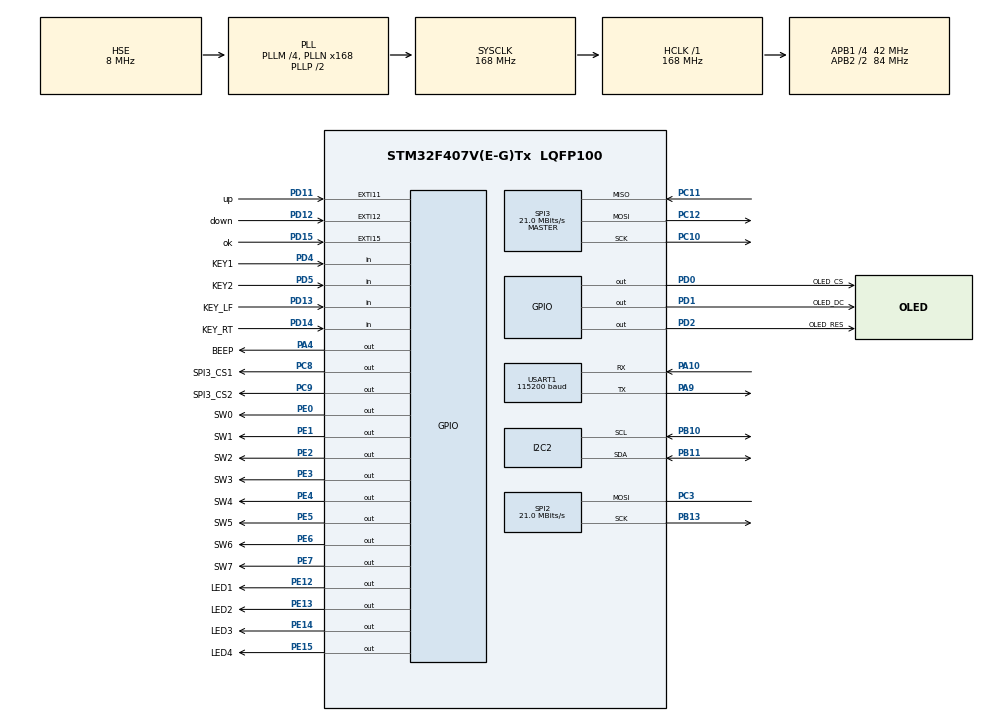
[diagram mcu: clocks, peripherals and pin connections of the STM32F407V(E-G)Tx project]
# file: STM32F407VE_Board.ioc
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Mcu.Family=STM32F4
Mcu.Name=STM32F407V(E-G)Tx
Mcu.Package=LQFP100
NVIC.EXTI15_10_IRQn=true\:6\:0\:true\:false\:true\:true\:true
NVIC.PriorityGroup=NVIC_PRIORITYGROUP_4
NVIC.USART1_IRQn=true\:2\:0\:true\:false\:true\:true\:true
PA10.Mode=Asynchronous
PA10.Signal=USART1_RX
PA13.Mode=Serial_Wire
PA13.Signal=SYS_JTMS-SWDIO
PA14.Mode=Serial_Wire
PA14.Signal=SYS_JTCK-SWCLK
PA4.GPIO_Label=BEEP
PA4.GPIO_PuPd=GPIO_PULLUP
PA4.Signal=GPIO_Output
PA9.Mode=Asynchronous
PA9.Signal=USART1_TX
PB10.Mode=I2C
PB10.Signal=I2C2_SCL
PB11.Mode=I2C
PB11.Signal=I2C2_SDA
PB13.Mode=Simplex_Bidirectional_Master
PB13.Signal=SPI2_SCK
PC10.Mode=Full_Duplex_Master
PC10.Signal=SPI3_SCK
PC11.Mode=Full_Duplex_Master
PC11.Signal=SPI3_MISO
PC12.Mode=Full_Duplex_Master
PC12.Signal=SPI3_MOSI
PC3.Mode=Simplex_Bidirectional_Master
PC3.Signal=SPI2_MOSI
PC8.GPIO_Label=SPI3_CS1
PC8.GPIO_PuPd=GPIO_PULLUP
PC8.PinState=GPIO_PIN_SET
PC8.Signal=GPIO_Output
PC9.GPIO_Label=SPI3_CS2
PC9.GPIO_PuPd=GPIO_PULLUP
PC9.PinState=GPIO_PIN_SET
PC9.Signal=GPIO_Output
PD0.GPIO_Label=OLED_CS
PD0.GPIO_PuPd=GPIO_PULLUP
PD0.PinState=GPIO_PIN_SET
PD0.Signal=GPIO_Output
PD1.GPIO_Label=OLED_DC
PD1.GPIO_PuPd=GPIO_PULLUP
PD1.PinState=GPIO_PIN_SET
PD1.Signal=GPIO_Output
PD11.GPIO_Label=up
PD11.GPIO_ModeDefaultEXTI=GPIO_MODE_IT_FALLING
PD11.GPIO_PuPd=GPIO_PULLUP
PD11.Signal=GPXTI11
PD12.GPIO_Label=down
PD12.GPIO_ModeDefaultEXTI=GPIO_MODE_IT_FALLING
PD12.GPIO_PuPd=GPIO_PULLUP
PD12.Signal=GPXTI12
PD13.GPIO_Label=KEY_LF
PD13.GPIO_PuPd=GPIO_PULLUP
PD13.Signal=GPIO_Input
PD14.GPIO_Label=KEY_RT
PD14.GPIO_PuPd=GPIO_PULLUP
PD14.Signal=GPIO_Input
PD15.GPIO_Label=ok
PD15.GPIO_ModeDefaultEXTI=GPIO_MODE_IT_FALLING
PD15.GPIO_PuPd=GPIO_PULLUP
PD15.Signal=GPXTI15
PD2.GPIO_Label=OLED_RES
PD2.GPIO_PuPd=GPIO_PULLUP
PD2.PinState=GPIO_PIN_SET
PD2.Signal=GPIO_Output
PD4.GPIO_Label=KEY1
PD4.GPIO_PuPd=GPIO_PULLUP
PD4.Signal=GPIO_Input
PD5.GPIO_Label=KEY2
PD5.GPIO_PuPd=GPIO_PULLUP
PD5.Signal=GPIO_Input
PE0.GPIO_Label=SW0
PE0.GPIO_PuPd=GPIO_PULLUP
PE0.PinState=GPIO_PIN_SET
PE0.Signal=GPIO_Output
PE1.GPIO_Label=SW1
PE1.GPIO_PuPd=GPIO_PULLUP
PE1.PinState=GPIO_PIN_SET
PE1.Signal=GPIO_Output
PE12.GPIO_Label=LED1
PE12.GPIO_PuPd=GPIO_PULLUP
PE12.PinState=GPIO_PIN_SET
PE12.Signal=GPIO_Output
PE13.GPIO_Label=LED2
PE13.GPIO_PuPd=GPIO_PULLUP
PE13.PinState=GPIO_PIN_SET
PE13.Signal=GPIO_Output
PE14.GPIO_Label=LED3
PE14.GPIO_PuPd=GPIO_PULLUP
PE14.PinState=GPIO_PIN_SET
PE14.Signal=GPIO_Output
PE15.GPIO_Label=LED4
PE15.GPIO_PuPd=GPIO_PULLUP
PE15.PinState=GPIO_PIN_SET
PE15.Signal=GPIO_Output
PE2.GPIO_Label=SW2
PE2.GPIO_PuPd=GPIO_PULLUP
PE2.PinState=GPIO_PIN_SET
PE2.Signal=GPIO_Output
PE3.GPIO_Label=SW3
PE3.GPIO_PuPd=GPIO_PULLUP
PE3.PinState=GPIO_PIN_SET
PE3.Signal=GPIO_Output
PE4.GPIO_Label=SW4
PE4.GPIO_PuPd=GPIO_PULLUP
PE4.PinState=GPIO_PIN_SET
PE4.Signal=GPIO_Output
PE5.GPIO_Label=SW5
PE5.GPIO_PuPd=GPIO_PULLUP
PE5.PinState=GPIO_PIN_SET
PE5.Signal=GPIO_Output
PE6.GPIO_Label=SW6
PE6.GPIO_PuPd=GPIO_PULLUP
PE6.PinState=GPIO_PIN_SET
PE6.Signal=GPIO_Output
PE7.GPIO_Label=SW7
PE7.GPIO_PuPd=GPIO_PULLUP
PE7.PinState=GPIO_PIN_SET
PE7.Signal=GPIO_Output
PH0-OSC_IN.Mode=HSE-External-Oscillator
PH0-OSC_IN.Signal=RCC_OSC_IN
PH1-OSC_OUT.Mode=HSE-External-Oscillator
PH1-OSC_OUT.Signal=RCC_OSC_OUT
ProjectManager.HeapSize=0x200
ProjectManager.StackSize=0x400
ProjectManager.TargetToolchain=MDK-ARM V5.27
RCC.48MHZClocksFreq_Value=84000000
RCC.AHBFreq_Value=168000000
RCC.APB1CLKDivider=RCC_HCLK_DIV4
RCC.APB1Freq_Value=42000000
RCC.APB1TimFreq_Value=84000000
RCC.APB2CLKDivider=RCC_HCLK_DIV2
RCC.APB2Freq_Value=84000000
RCC.APB2TimFreq_Value=168000000
RCC.CortexFreq_Value=168000000
RCC.HCLKFreq_Value=168000000
RCC.HSE_VALUE=8000000
RCC.HSI_VALUE=16000000
RCC.LSE_VALUE=32768
RCC.PLLM=4
RCC.PLLN=168
RCC.PLLSourceVirtual=RCC_PLLSOURCE_HSE
RCC.SYSCLKFreq_VALUE=168000000
RCC.SYSCLKSource=RCC_SYSCLKSOURCE_PLLCLK
RCC.VCOOutputFreq_Value=336000000
SPI2.CalculateBaudRate=21.0 MBits/s
SPI2.Direction=SPI_DIRECTION_1LINE
SPI2.Mode=SPI_MODE_MASTER
SPI2.VirtualType=VM_MASTER
SPI3.CalculateBaudRate=21.0 MBits/s
SPI3.Direction=SPI_DIRECTION_2LINES
SPI3.Mode=SPI_MODE_MASTER
SPI3.VirtualType=VM_MASTER
USART1.BaudRate=115200
USART1.VirtualMode=VM_ASYNC
board=custom

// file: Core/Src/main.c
/* USER CODE BEGIN Header */
/**
  ******************************************************************************
  * @file           : main.c
  * @brief          : Main program body
  ******************************************************************************
  * @attention
  *
  * <h2><center>&copy; Copyright (c) 2021 STMicroelectronics.
  * All rights reserved.</center></h2>
  *
  * This software component is licensed by ST under BSD 3-Clause license,
  * the "License"; You may not use this file except in compliance with the
  * License. You may obtain a copy of the License at:
  *                        opensource.org/licenses/BSD-3-Clause
  *
  ******************************************************************************
  */
/* USER CODE END Header */
#include "main.h"

/* USER CODE BEGIN Includes */

#include "ssd1306.h"
#include <stdbool.h>
#include <stdio.h>
#include "menu.h"

/* USER CODE END Includes */

I2C_HandleTypeDef hi2c2;

SPI_HandleTypeDef hspi2;
SPI_HandleTypeDef hspi3;

UART_HandleTypeDef huart1;

void SystemClock_Config(void);
static void MX_GPIO_Init(void);
static void MX_USART1_UART_Init(void);
static void MX_I2C2_Init(void);
static void MX_SPI2_Init(void);
static void MX_SPI3_Init(void);

int main(void)
{

  /* MCU Configuration--------------------------------------------------------*/

  /* Reset of all peripherals, Initializes the Flash interface and the Systick. */
  HAL_Init();

  /* Configure the system clock */
  SystemClock_Config();

  /* Initialize all configured peripherals */
  MX_GPIO_Init();
  MX_USART1_UART_Init();
  MX_I2C2_Init();
  MX_SPI2_Init();
  MX_SPI3_Init();

  /* Infinite loop */
  /* USER CODE BEGIN WHILE */
	ssd1306_Init();

	RenewMenu(0,0,0);

  while (1)
  {
//

    /* USER CODE END WHILE */

  }
}

void SystemClock_Config(void)
{
  RCC_OscInitTypeDef RCC_OscInitStruct = {0};
  RCC_ClkInitTypeDef RCC_ClkInitStruct = {0};

  /** Configure the main internal regulator output voltage
  */
  __HAL_RCC_PWR_CLK_ENABLE();
  __HAL_PWR_VOLTAGESCALING_CONFIG(PWR_REGULATOR_VOLTAGE_SCALE1);
  /** Initializes the RCC Oscillators according to the specified parameters
  * in the RCC_OscInitTypeDef structure.
  */
  RCC_OscInitStruct.OscillatorType = RCC_OSCILLATORTYPE_HSE;
  RCC_OscInitStruct.HSEState = RCC_HSE_ON;
  RCC_OscInitStruct.PLL.PLLState = RCC_PLL_ON;
  RCC_OscInitStruct.PLL.PLLSource = RCC_PLLSOURCE_HSE;
  RCC_OscInitStruct.PLL.PLLM = 4;
  RCC_OscInitStruct.PLL.PLLN = 168;
  RCC_OscInitStruct.PLL.PLLP = RCC_PLLP_DIV2;
  RCC_OscInitStruct.PLL.PLLQ = 4;
  if (HAL_RCC_OscConfig(&RCC_OscInitStruct) != HAL_OK)
  {
    Error_Handler();
  }
  /** Initializes the CPU, AHB and APB buses clocks
  */
  RCC_ClkInitStruct.ClockType = RCC_CLOCKTYPE_HCLK|RCC_CLOCKTYPE_SYSCLK
                              |RCC_CLOCKTYPE_PCLK1|RCC_CLOCKTYPE_PCLK2;
  RCC_ClkInitStruct.SYSCLKSource = RCC_SYSCLKSOURCE_PLLCLK;
  RCC_ClkInitStruct.AHBCLKDivider = RCC_SYSCLK_DIV1;
  RCC_ClkInitStruct.APB1CLKDivider = RCC_HCLK_DIV4;
  RCC_ClkInitStruct.APB2CLKDivider = RCC_HCLK_DIV2;

  if (HAL_RCC_ClockConfig(&RCC_ClkInitStruct, FLASH_LATENCY_5) != HAL_OK)
  {
    Error_Handler();
  }
}

static void MX_I2C2_Init(void)
{

  hi2c2.Instance = I2C2;
  hi2c2.Init.ClockSpeed = 100000;
  hi2c2.Init.DutyCycle = I2C_DUTYCYCLE_2;
  hi2c2.Init.OwnAddress1 = 0;
  hi2c2.Init.AddressingMode = I2C_ADDRESSINGMODE_7BIT;
  hi2c2.Init.DualAddressMode = I2C_DUALADDRESS_DISABLE;
  hi2c2.Init.OwnAddress2 = 0;
  hi2c2.Init.GeneralCallMode = I2C_GENERALCALL_DISABLE;
  hi2c2.Init.NoStretchMode = I2C_NOSTRETCH_DISABLE;
  if (HAL_I2C_Init(&hi2c2) != HAL_OK)
  {
    Error_Handler();
  }

}

static void MX_SPI2_Init(void)
{

  /* SPI2 parameter configuration*/
  hspi2.Instance = SPI2;
  hspi2.Init.Mode = SPI_MODE_MASTER;
  hspi2.Init.Direction = SPI_DIRECTION_1LINE;
  hspi2.Init.DataSize = SPI_DATASIZE_8BIT;
  hspi2.Init.CLKPolarity = SPI_POLARITY_LOW;
  hspi2.Init.CLKPhase = SPI_PHASE_1EDGE;
  hspi2.Init.NSS = SPI_NSS_SOFT;
  hspi2.Init.BaudRatePrescaler = SPI_BAUDRATEPRESCALER_2;
  hspi2.Init.FirstBit = SPI_FIRSTBIT_MSB;
  hspi2.Init.TIMode = SPI_TIMODE_DISABLE;
  hspi2.Init.CRCCalculation = SPI_CRCCALCULATION_DISABLE;
  hspi2.Init.CRCPolynomial = 10;
  if (HAL_SPI_Init(&hspi2) != HAL_OK)
  {
    Error_Handler();
  }

}

static void MX_SPI3_Init(void)
{

  /* SPI3 parameter configuration*/
  hspi3.Instance = SPI3;
  hspi3.Init.Mode = SPI_MODE_MASTER;
  hspi3.Init.Direction = SPI_DIRECTION_2LINES;
  hspi3.Init.DataSize = SPI_DATASIZE_8BIT;
  hspi3.Init.CLKPolarity = SPI_POLARITY_LOW;
  hspi3.Init.CLKPhase = SPI_PHASE_1EDGE;
  hspi3.Init.NSS = SPI_NSS_SOFT;
  hspi3.Init.BaudRatePrescaler = SPI_BAUDRATEPRESCALER_2;
  hspi3.Init.FirstBit = SPI_FIRSTBIT_MSB;
  hspi3.Init.TIMode = SPI_TIMODE_DISABLE;
  hspi3.Init.CRCCalculation = SPI_CRCCALCULATION_DISABLE;
  hspi3.Init.CRCPolynomial = 10;
  if (HAL_SPI_Init(&hspi3) != HAL_OK)
  {
    Error_Handler();
  }

}

static void MX_USART1_UART_Init(void)
{

  huart1.Instance = USART1;
  huart1.Init.BaudRate = 115200;
  huart1.Init.WordLength = UART_WORDLENGTH_8B;
  huart1.Init.StopBits = UART_STOPBITS_1;
  huart1.Init.Parity = UART_PARITY_NONE;
  huart1.Init.Mode = UART_MODE_TX_RX;
  huart1.Init.HwFlowCtl = UART_HWCONTROL_NONE;
  huart1.Init.OverSampling = UART_OVERSAMPLING_16;
  if (HAL_UART_Init(&huart1) != HAL_OK)
  {
    Error_Handler();
  }

}

static void MX_GPIO_Init(void)
{
  GPIO_InitTypeDef GPIO_InitStruct = {0};

  /* GPIO Ports Clock Enable */
  __HAL_RCC_GPIOE_CLK_ENABLE();
  __HAL_RCC_GPIOH_CLK_ENABLE();
  __HAL_RCC_GPIOC_CLK_ENABLE();
  __HAL_RCC_GPIOA_CLK_ENABLE();
  __HAL_RCC_GPIOB_CLK_ENABLE();
  __HAL_RCC_GPIOD_CLK_ENABLE();

  /*Configure GPIO pin Output Level */
  HAL_GPIO_WritePin(GPIOE, SW2_Pin|SW3_Pin|SW4_Pin|SW5_Pin
                          |SW6_Pin|SW7_Pin|LED1_Pin|LED2_Pin
                          |LED3_Pin|LED4_Pin|SW0_Pin|SW1_Pin, GPIO_PIN_SET);

  /*Configure GPIO pin Output Level */
  HAL_GPIO_WritePin(BEEP_GPIO_Port, BEEP_Pin, GPIO_PIN_RESET);

  /*Configure GPIO pin Output Level */
  HAL_GPIO_WritePin(GPIOC, SPI3_CS1_Pin|SPI3_CS2_Pin, GPIO_PIN_SET);

  /*Configure GPIO pin Output Level */
  HAL_GPIO_WritePin(GPIOD, OLED_CS_Pin|OLED_DC_Pin|OLED_RES_Pin, GPIO_PIN_SET);

  /*Configure GPIO pins : SW2_Pin SW3_Pin SW4_Pin SW5_Pin
                           SW6_Pin SW7_Pin LED1_Pin LED2_Pin
                           LED3_Pin LED4_Pin SW0_Pin SW1_Pin */
  GPIO_InitStruct.Pin = SW2_Pin|SW3_Pin|SW4_Pin|SW5_Pin
                          |SW6_Pin|SW7_Pin|LED1_Pin|LED2_Pin
                          |LED3_Pin|LED4_Pin|SW0_Pin|SW1_Pin;
  GPIO_InitStruct.Mode = GPIO_MODE_OUTPUT_PP;
  GPIO_InitStruct.Pull = GPIO_PULLUP;
  GPIO_InitStruct.Speed = GPIO_SPEED_FREQ_LOW;
  HAL_GPIO_Init(GPIOE, &GPIO_InitStruct);

  /*Configure GPIO pin : BEEP_Pin */
  GPIO_InitStruct.Pin = BEEP_Pin;
  GPIO_InitStruct.Mode = GPIO_MODE_OUTPUT_PP;
  GPIO_InitStruct.Pull = GPIO_PULLUP;
  GPIO_InitStruct.Speed = GPIO_SPEED_FREQ_LOW;
  HAL_GPIO_Init(BEEP_GPIO_Port, &GPIO_InitStruct);

  /*Configure GPIO pins : up_Pin down_Pin ok_Pin */
  GPIO_InitStruct.Pin = up_Pin|down_Pin|ok_Pin;
  GPIO_InitStruct.Mode = GPIO_MODE_IT_FALLING;
  GPIO_InitStruct.Pull = GPIO_PULLUP;
  HAL_GPIO_Init(GPIOD, &GPIO_InitStruct);

  /*Configure GPIO pins : KEY_LF_Pin KEY_RT_Pin KEY1_Pin KEY2_Pin */
  GPIO_InitStruct.Pin = KEY_LF_Pin|KEY_RT_Pin|KEY1_Pin|KEY2_Pin;
  GPIO_InitStruct.Mode = GPIO_MODE_INPUT;
  GPIO_InitStruct.Pull = GPIO_PULLUP;
  HAL_GPIO_Init(GPIOD, &GPIO_InitStruct);

  /*Configure GPIO pins : SPI3_CS1_Pin SPI3_CS2_Pin */
  GPIO_InitStruct.Pin = SPI3_CS1_Pin|SPI3_CS2_Pin;
  GPIO_InitStruct.Mode = GPIO_MODE_OUTPUT_PP;
  GPIO_InitStruct.Pull = GPIO_PULLUP;
  GPIO_InitStruct.Speed = GPIO_SPEED_FREQ_LOW;
  HAL_GPIO_Init(GPIOC, &GPIO_InitStruct);

  /*Configure GPIO pins : OLED_CS_Pin OLED_DC_Pin OLED_RES_Pin */
  GPIO_InitStruct.Pin = OLED_CS_Pin|OLED_DC_Pin|OLED_RES_Pin;
  GPIO_InitStruct.Mode = GPIO_MODE_OUTPUT_PP;
  GPIO_InitStruct.Pull = GPIO_PULLUP;
  GPIO_InitStruct.Speed = GPIO_SPEED_FREQ_LOW;
  HAL_GPIO_Init(GPIOD, &GPIO_InitStruct);

  /* EXTI interrupt init*/
  HAL_NVIC_SetPriority(EXTI15_10_IRQn, 6, 0);
  HAL_NVIC_EnableIRQ(EXTI15_10_IRQn);

}

void Error_Handler(void)
{
  __disable_irq();
  while (1)
  {
  }
}

/************************ (C) COPYRIGHT STMicroelectronics *****END OF FILE****/
